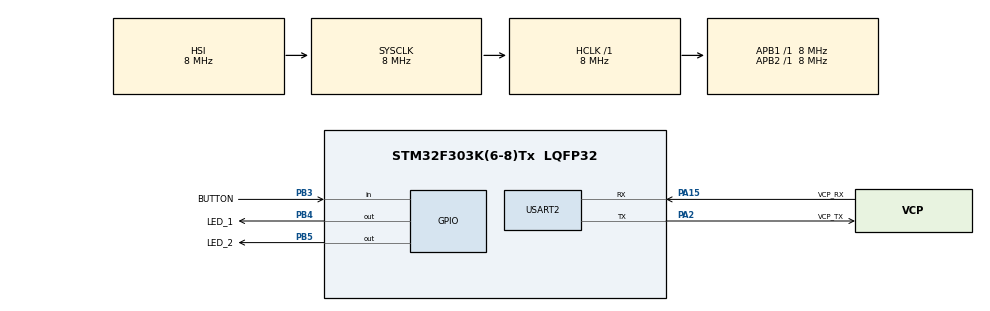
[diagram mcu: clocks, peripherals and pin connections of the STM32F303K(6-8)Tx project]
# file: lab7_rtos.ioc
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FREERTOS.Tasks01=defaultTask,24,128,StartDefaultTask,Default,NULL,Dynamic,NULL,NULL;blink_1,24,128,start_blink_1,Default,NULL,Dynamic,NULL,NULL;blink_2,16,128,start_blink_2,Default,NULL,Dynamic,NULL,NULL;print_button,32,128,start_print_button,Default,NULL,Dynamic,NULL,NULL
FREERTOS.configUSE_NEWLIB_REENTRANT=1
Mcu.Family=STM32F3
Mcu.Name=STM32F303K(6-8)Tx
Mcu.Package=LQFP32
NVIC.PriorityGroup=NVIC_PRIORITYGROUP_4
NVIC.TIM6_DAC1_IRQn=true\:15\:0\:false\:false\:true\:false\:false\:true\:true
NVIC.TimeBase=TIM6_DAC1_IRQn
NVIC.TimeBaseIP=TIM6
PA13.GPIO_Label=SWDIO
PA13.Mode=Serial_Wire
PA13.Signal=SYS_JTMS-SWDIO
PA14.GPIO_Label=SWCLK
PA14.Mode=Serial_Wire
PA14.Signal=SYS_JTCK-SWCLK
PA15.GPIO_Label=VCP_RX
PA15.Mode=Asynchronous
PA15.Signal=USART2_RX
PA2.GPIO_Label=VCP_TX
PA2.Mode=Asynchronous
PA2.Signal=USART2_TX
PB3.GPIO_Label=BUTTON
PB3.GPIO_PuPd=GPIO_PULLDOWN
PB3.Signal=GPIO_Input
PB4.GPIO_Label=LED_1
PB4.Signal=GPIO_Output
PB5.GPIO_Label=LED_2
PB5.Signal=GPIO_Output
PF0\ /\ OSC_IN.GPIO_Label=MCO
PF0\ /\ OSC_IN.Mode=HSE-External-Clock-Source
PF0\ /\ OSC_IN.Signal=RCC_OSC_IN
ProjectManager.HeapSize=0x200
ProjectManager.StackSize=0x400
ProjectManager.TargetToolchain=STM32CubeIDE
RCC.AHBFreq_Value=8000000
RCC.APB1Freq_Value=8000000
RCC.APB2Freq_Value=8000000
RCC.CortexFreq_Value=8000000
RCC.HSE_VALUE=8000000
RCC.HSI_VALUE=8000000
RCC.SYSCLKFreq_VALUE=8000000
USART2.VirtualMode-Asynchronous=VM_ASYNC
VP_FREERTOS_VS_CMSIS_V2.Mode=CMSIS_V2
VP_SYS_VS_tim6.Mode=TIM6
board=NUCLEO-F303K8

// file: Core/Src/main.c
/* USER CODE BEGIN Header */
/**
  ******************************************************************************
  * @file           : main.c
  * @brief          : Main program body
  ******************************************************************************
  * @attention
  *
  * Copyright (c) 2024 STMicroelectronics.
  * All rights reserved.
  *
  * This software is licensed under terms that can be found in the LICENSE file
  * in the root directory of this software component.
  * If no LICENSE file comes with this software, it is provided AS-IS.
  *
  ******************************************************************************
  */
/* USER CODE END Header */
#include "main.h"
#include "cmsis_os.h"
#include <string.h>

UART_HandleTypeDef huart2;

/* Definitions for defaultTask */
osThreadId_t defaultTaskHandle;
const osThreadAttr_t defaultTask_attributes = {
  .name = "defaultTask",
  .stack_size = 128 * 4,
  .priority = (osPriority_t) osPriorityNormal,
};
/* Definitions for blink_1 */
osThreadId_t blink_1Handle;
const osThreadAttr_t blink_1_attributes = {
  .name = "blink_1",
  .stack_size = 128 * 4,
  .priority = (osPriority_t) osPriorityNormal,
};
/* Definitions for blink_2 */
osThreadId_t blink_2Handle;
const osThreadAttr_t blink_2_attributes = {
  .name = "blink_2",
  .stack_size = 128 * 4,
  .priority = (osPriority_t) osPriorityBelowNormal,
};
/* Definitions for print_button */
osThreadId_t print_buttonHandle;
const osThreadAttr_t print_button_attributes = {
  .name = "print_button",
  .stack_size = 128 * 4,
  .priority = (osPriority_t) osPriorityAboveNormal,
};

void SystemClock_Config(void);
static void MX_GPIO_Init(void);
static void MX_USART2_UART_Init(void);
void StartDefaultTask(void *argument);
void start_blink_1(void *argument);
void start_blink_2(void *argument);
void start_print_button(void *argument);

int main(void)
{

  /* MCU Configuration--------------------------------------------------------*/

  /* Reset of all peripherals, Initializes the Flash interface and the Systick. */
  HAL_Init();

  /* Configure the system clock */
  SystemClock_Config();

  /* Initialize all configured peripherals */
  MX_GPIO_Init();
  MX_USART2_UART_Init();

  /* Init scheduler */
  osKernelInitialize();

  /* Create the thread(s) */
  /* creation of defaultTask */
  defaultTaskHandle = osThreadNew(StartDefaultTask, NULL, &defaultTask_attributes);

  /* creation of blink_1 */
  blink_1Handle = osThreadNew(start_blink_1, NULL, &blink_1_attributes);

  /* creation of blink_2 */
  blink_2Handle = osThreadNew(start_blink_2, NULL, &blink_2_attributes);

  /* creation of print_button */
  print_buttonHandle = osThreadNew(start_print_button, NULL, &print_button_attributes);

  /* Start scheduler */
  osKernelStart();

  /* We should never get here as control is now taken by the scheduler */

  /* Infinite loop */
  while (1)
  {

  }
}

void SystemClock_Config(void)
{
  RCC_OscInitTypeDef RCC_OscInitStruct = {0};
  RCC_ClkInitTypeDef RCC_ClkInitStruct = {0};

  /** Initializes the RCC Oscillators according to the specified parameters
  * in the RCC_OscInitTypeDef structure.
  */
  RCC_OscInitStruct.OscillatorType = RCC_OSCILLATORTYPE_HSI;
  RCC_OscInitStruct.HSIState = RCC_HSI_ON;
  RCC_OscInitStruct.HSICalibrationValue = RCC_HSICALIBRATION_DEFAULT;
  RCC_OscInitStruct.PLL.PLLState = RCC_PLL_NONE;
  if (HAL_RCC_OscConfig(&RCC_OscInitStruct) != HAL_OK)
  {
    Error_Handler();
  }

  /** Initializes the CPU, AHB and APB buses clocks
  */
  RCC_ClkInitStruct.ClockType = RCC_CLOCKTYPE_HCLK|RCC_CLOCKTYPE_SYSCLK
                              |RCC_CLOCKTYPE_PCLK1|RCC_CLOCKTYPE_PCLK2;
  RCC_ClkInitStruct.SYSCLKSource = RCC_SYSCLKSOURCE_HSI;
  RCC_ClkInitStruct.AHBCLKDivider = RCC_SYSCLK_DIV1;
  RCC_ClkInitStruct.APB1CLKDivider = RCC_HCLK_DIV1;
  RCC_ClkInitStruct.APB2CLKDivider = RCC_HCLK_DIV1;

  if (HAL_RCC_ClockConfig(&RCC_ClkInitStruct, FLASH_LATENCY_0) != HAL_OK)
  {
    Error_Handler();
  }
}

static void MX_USART2_UART_Init(void)
{

  huart2.Instance = USART2;
  huart2.Init.BaudRate = 38400;
  huart2.Init.WordLength = UART_WORDLENGTH_8B;
  huart2.Init.StopBits = UART_STOPBITS_1;
  huart2.Init.Parity = UART_PARITY_NONE;
  huart2.Init.Mode = UART_MODE_TX_RX;
  huart2.Init.HwFlowCtl = UART_HWCONTROL_NONE;
  huart2.Init.OverSampling = UART_OVERSAMPLING_16;
  huart2.Init.OneBitSampling = UART_ONE_BIT_SAMPLE_DISABLE;
  huart2.AdvancedInit.AdvFeatureInit = UART_ADVFEATURE_NO_INIT;
  if (HAL_UART_Init(&huart2) != HAL_OK)
  {
    Error_Handler();
  }

}

static void MX_GPIO_Init(void)
{
  GPIO_InitTypeDef GPIO_InitStruct = {0};

  /* GPIO Ports Clock Enable */
  __HAL_RCC_GPIOF_CLK_ENABLE();
  __HAL_RCC_GPIOA_CLK_ENABLE();
  __HAL_RCC_GPIOB_CLK_ENABLE();

  /*Configure GPIO pin Output Level */
  HAL_GPIO_WritePin(GPIOB, LED_1_Pin|LED_2_Pin, GPIO_PIN_RESET);

  /*Configure GPIO pin : BUTTON_Pin */
  GPIO_InitStruct.Pin = BUTTON_Pin;
  GPIO_InitStruct.Mode = GPIO_MODE_INPUT;
  GPIO_InitStruct.Pull = GPIO_PULLDOWN;
  HAL_GPIO_Init(BUTTON_GPIO_Port, &GPIO_InitStruct);

  /*Configure GPIO pins : LED_1_Pin LED_2_Pin */
  GPIO_InitStruct.Pin = LED_1_Pin|LED_2_Pin;
  GPIO_InitStruct.Mode = GPIO_MODE_OUTPUT_PP;
  GPIO_InitStruct.Pull = GPIO_NOPULL;
  GPIO_InitStruct.Speed = GPIO_SPEED_FREQ_LOW;
  HAL_GPIO_Init(GPIOB, &GPIO_InitStruct);

}

void StartDefaultTask(void *argument)
{
  for(;;)
  {
    osDelay(1);
  }
}

void start_blink_1(void *argument)
{
  /* USER CODE BEGIN start_blink_1 */
  /* Infinite loop */
  for(;;)
  {
    HAL_GPIO_TogglePin(LED_1_GPIO_Port, LED_1_Pin);
    osDelay(BLINK_1_PERIOD/2);
  }
  /* USER CODE END start_blink_1 */
}

void start_blink_2(void *argument)
{
  /* USER CODE BEGIN start_blink_2 */
  /* Infinite loop */
  for(;;)
  {
    HAL_GPIO_TogglePin(LED_2_GPIO_Port, LED_2_Pin);
    osDelay(BLINK_2_PERIOD/2);
  }
  /* USER CODE END start_blink_2 */
}

void start_print_button(void *argument)
{
  /* USER CODE BEGIN start_print_button */
  char press_msg[] = "Button Pressed!";
  /* Infinite loop */
  for(;;)
  {
    // Read using Input Data Register
    // IDR & 0x0000_0008U (Check if Pin 3 of the GPIO Port B Input Data Register == 1)
    if (BUTTON_GPIO_Port->IDR & BUTTON_Pin) {
      HAL_UART_Transmit(&huart2, (uint8_t*)press_msg, strlen(press_msg), HAL_TX_TIMEOUT);
      osDelay(DEBOUNCE_DELAY);
    }
    osDelay(1);
  }
  /* USER CODE END start_print_button */
}

void HAL_TIM_PeriodElapsedCallback(TIM_HandleTypeDef *htim)
{
  if (htim->Instance == TIM6) {
    HAL_IncTick();
  }
}

void Error_Handler(void)
{
  __disable_irq();
  while (1)
  {
  }
}
